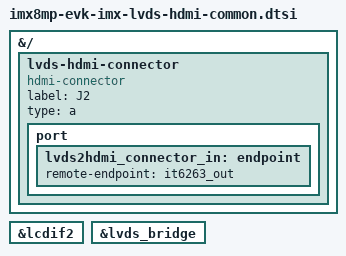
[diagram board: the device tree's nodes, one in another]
// SPDX-License-Identifier: (GPL-2.0+ OR MIT)
/*
 * Copyright 2024 NXP
 */

/dts-v1/;
/plugin/;

&{/} {
	lvds-hdmi-connector {
		compatible = "hdmi-connector";
		label = "J2";
		type = "a";

		port {
			lvds2hdmi_connector_in: endpoint {
				remote-endpoint = <&it6263_out>;
			};
		};
	};
};

&lcdif2 {
	status = "okay";
};

&lvds_bridge {
	status = "okay";
};
